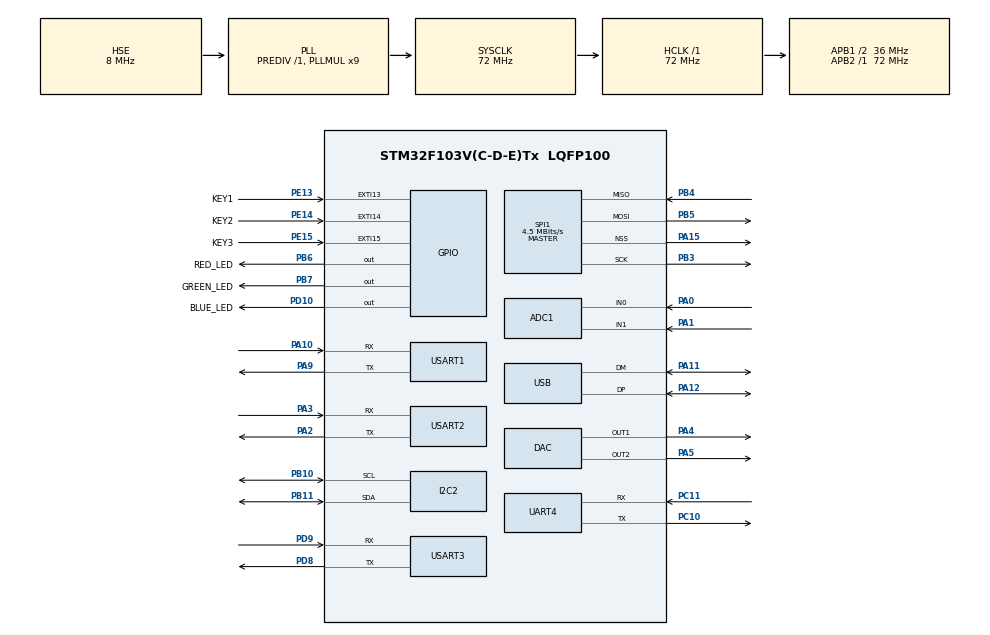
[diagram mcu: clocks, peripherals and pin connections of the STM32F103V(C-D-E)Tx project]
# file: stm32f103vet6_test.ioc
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ADC1.Channel-0\#ChannelRegularConversion=ADC_CHANNEL_0
ADC1.Channel-1\#ChannelRegularConversion=ADC_CHANNEL_1
ADC1.ContinuousConvMode=ENABLE
ADC1.EnableInjectedConversion=DISABLE
ADC1.ExternalTrigConv=ADC_SOFTWARE_START
ADC1.NbrOfConversion=2
ADC1.NbrOfConversionFlag=1
ADC1.Rank-0\#ChannelRegularConversion=1
ADC1.Rank-1\#ChannelRegularConversion=2
ADC1.SamplingTime-0\#ChannelRegularConversion=ADC_SAMPLETIME_55CYCLES_5
ADC1.SamplingTime-1\#ChannelRegularConversion=ADC_SAMPLETIME_55CYCLES_5
ADC1.master=1
Dma.ADC1.0.Direction=DMA_PERIPH_TO_MEMORY
Dma.ADC1.0.Instance=DMA1_Channel1
Dma.ADC1.0.MemDataAlignment=DMA_MDATAALIGN_HALFWORD
Dma.ADC1.0.MemInc=DMA_MINC_ENABLE
Dma.ADC1.0.Mode=DMA_CIRCULAR
Dma.ADC1.0.PeriphDataAlignment=DMA_PDATAALIGN_HALFWORD
Dma.ADC1.0.PeriphInc=DMA_PINC_DISABLE
Dma.ADC1.0.Priority=DMA_PRIORITY_LOW
Dma.Request0=ADC1
Dma.Request1=USART2_RX
Dma.Request2=USART2_TX
Dma.Request3=USART3_RX
Dma.Request4=USART3_TX
Dma.Request5=USART1_RX
Dma.Request6=USART1_TX
Dma.Request7=UART4_RX
Dma.Request8=UART4_TX
Dma.UART4_RX.7.Direction=DMA_PERIPH_TO_MEMORY
Dma.UART4_RX.7.Instance=DMA2_Channel3
Dma.UART4_RX.7.MemDataAlignment=DMA_MDATAALIGN_BYTE
Dma.UART4_RX.7.MemInc=DMA_MINC_ENABLE
Dma.UART4_RX.7.Mode=DMA_NORMAL
Dma.UART4_RX.7.PeriphDataAlignment=DMA_PDATAALIGN_BYTE
Dma.UART4_RX.7.PeriphInc=DMA_PINC_DISABLE
Dma.UART4_RX.7.Priority=DMA_PRIORITY_LOW
Dma.UART4_TX.8.Direction=DMA_MEMORY_TO_PERIPH
Dma.UART4_TX.8.Instance=DMA2_Channel5
Dma.UART4_TX.8.MemDataAlignment=DMA_MDATAALIGN_BYTE
Dma.UART4_TX.8.MemInc=DMA_MINC_ENABLE
Dma.UART4_TX.8.Mode=DMA_NORMAL
Dma.UART4_TX.8.PeriphDataAlignment=DMA_PDATAALIGN_BYTE
Dma.UART4_TX.8.PeriphInc=DMA_PINC_DISABLE
Dma.UART4_TX.8.Priority=DMA_PRIORITY_LOW
Dma.USART1_RX.5.Direction=DMA_PERIPH_TO_MEMORY
Dma.USART1_RX.5.Instance=DMA1_Channel5
Dma.USART1_RX.5.MemDataAlignment=DMA_MDATAALIGN_BYTE
Dma.USART1_RX.5.MemInc=DMA_MINC_ENABLE
Dma.USART1_RX.5.Mode=DMA_NORMAL
Dma.USART1_RX.5.PeriphDataAlignment=DMA_PDATAALIGN_BYTE
Dma.USART1_RX.5.PeriphInc=DMA_PINC_DISABLE
Dma.USART1_RX.5.Priority=DMA_PRIORITY_LOW
Dma.USART1_TX.6.Direction=DMA_MEMORY_TO_PERIPH
Dma.USART1_TX.6.Instance=DMA1_Channel4
Dma.USART1_TX.6.MemDataAlignment=DMA_MDATAALIGN_BYTE
Dma.USART1_TX.6.MemInc=DMA_MINC_ENABLE
Dma.USART1_TX.6.Mode=DMA_NORMAL
Dma.USART1_TX.6.PeriphDataAlignment=DMA_PDATAALIGN_BYTE
Dma.USART1_TX.6.PeriphInc=DMA_PINC_DISABLE
Dma.USART1_TX.6.Priority=DMA_PRIORITY_LOW
Dma.USART2_RX.1.Direction=DMA_PERIPH_TO_MEMORY
Dma.USART2_RX.1.Instance=DMA1_Channel6
Dma.USART2_RX.1.MemDataAlignment=DMA_MDATAALIGN_BYTE
Dma.USART2_RX.1.MemInc=DMA_MINC_ENABLE
Dma.USART2_RX.1.Mode=DMA_NORMAL
Dma.USART2_RX.1.PeriphDataAlignment=DMA_PDATAALIGN_BYTE
Dma.USART2_RX.1.PeriphInc=DMA_PINC_DISABLE
Dma.USART2_RX.1.Priority=DMA_PRIORITY_LOW
Dma.USART2_TX.2.Direction=DMA_MEMORY_TO_PERIPH
Dma.USART2_TX.2.Instance=DMA1_Channel7
Dma.USART2_TX.2.MemDataAlignment=DMA_MDATAALIGN_BYTE
Dma.USART2_TX.2.MemInc=DMA_MINC_ENABLE
Dma.USART2_TX.2.Mode=DMA_NORMAL
Dma.USART2_TX.2.PeriphDataAlignment=DMA_PDATAALIGN_BYTE
Dma.USART2_TX.2.PeriphInc=DMA_PINC_DISABLE
Dma.USART2_TX.2.Priority=DMA_PRIORITY_LOW
Dma.USART3_RX.3.Direction=DMA_PERIPH_TO_MEMORY
Dma.USART3_RX.3.Instance=DMA1_Channel3
Dma.USART3_RX.3.MemDataAlignment=DMA_MDATAALIGN_BYTE
Dma.USART3_RX.3.MemInc=DMA_MINC_ENABLE
Dma.USART3_RX.3.Mode=DMA_NORMAL
Dma.USART3_RX.3.PeriphDataAlignment=DMA_PDATAALIGN_BYTE
Dma.USART3_RX.3.PeriphInc=DMA_PINC_DISABLE
Dma.USART3_RX.3.Priority=DMA_PRIORITY_LOW
Dma.USART3_TX.4.Direction=DMA_MEMORY_TO_PERIPH
Dma.USART3_TX.4.Instance=DMA1_Channel2
Dma.USART3_TX.4.MemDataAlignment=DMA_MDATAALIGN_BYTE
Dma.USART3_TX.4.MemInc=DMA_MINC_ENABLE
Dma.USART3_TX.4.Mode=DMA_NORMAL
Dma.USART3_TX.4.PeriphDataAlignment=DMA_PDATAALIGN_BYTE
Dma.USART3_TX.4.PeriphInc=DMA_PINC_DISABLE
Dma.USART3_TX.4.Priority=DMA_PRIORITY_LOW
Mcu.Family=STM32F1
Mcu.Name=STM32F103V(C-D-E)Tx
Mcu.Package=LQFP100
NVIC.DMA1_Channel1_IRQn=true\:0\:0\:false\:false\:true\:false\:true\:true
NVIC.DMA1_Channel2_IRQn=true\:0\:0\:false\:false\:true\:false\:true\:true
NVIC.DMA1_Channel3_IRQn=true\:0\:0\:false\:false\:true\:false\:true\:true
NVIC.DMA1_Channel4_IRQn=true\:0\:0\:false\:false\:true\:false\:true\:true
NVIC.DMA1_Channel5_IRQn=true\:0\:0\:false\:false\:true\:false\:true\:true
NVIC.DMA1_Channel6_IRQn=true\:0\:0\:false\:false\:true\:false\:true\:true
NVIC.DMA1_Channel7_IRQn=true\:0\:0\:false\:false\:true\:false\:true\:true
NVIC.DMA2_Channel3_IRQn=true\:0\:0\:false\:false\:true\:false\:true\:true
NVIC.DMA2_Channel4_5_IRQn=true\:0\:0\:false\:false\:true\:false\:true\:true
NVIC.EXTI15_10_IRQn=true\:0\:0\:false\:false\:true\:true\:true\:true
NVIC.PriorityGroup=NVIC_PRIORITYGROUP_4
NVIC.UART4_IRQn=true\:0\:0\:false\:false\:true\:true\:true\:true
NVIC.USART1_IRQn=true\:0\:0\:false\:false\:true\:true\:true\:true
NVIC.USART2_IRQn=true\:0\:0\:false\:false\:true\:true\:true\:true
NVIC.USART3_IRQn=true\:0\:0\:false\:false\:true\:true\:true\:true
NVIC.USB_LP_CAN1_RX0_IRQn=true\:0\:0\:false\:false\:true\:false\:true\:true
OSC_IN.Mode=HSE-External-Oscillator
OSC_IN.Signal=RCC_OSC_IN
OSC_OUT.Mode=HSE-External-Oscillator
OSC_OUT.Signal=RCC_OSC_OUT
PA0-WKUP.Signal=ADCx_IN0
PA1.Signal=ADCx_IN1
PA10.Mode=Asynchronous
PA10.Signal=USART1_RX
PA11.Mode=Device
PA11.Signal=USB_DM
PA12.Mode=Device
PA12.Signal=USB_DP
PA13.Mode=Serial_Wire
PA13.Signal=SYS_JTMS-SWDIO
PA14.Mode=Serial_Wire
PA14.Signal=SYS_JTCK-SWCLK
PA15.Mode=NSS_Signal_Hard_Output
PA15.Signal=SPI1_NSS
PA2.Mode=Asynchronous
PA2.Signal=USART2_TX
PA3.Mode=Asynchronous
PA3.Signal=USART2_RX
PA4.Signal=COMP_DAC1_group
PA5.Signal=COMP_DAC2_group
PA9.Mode=Asynchronous
PA9.Signal=USART1_TX
PB10.Mode=I2C
PB10.Signal=I2C2_SCL
PB11.Mode=I2C
PB11.Signal=I2C2_SDA
PB3.Mode=Full_Duplex_Master
PB3.Signal=SPI1_SCK
PB4.Mode=Full_Duplex_Master
PB4.Signal=SPI1_MISO
PB5.Mode=Full_Duplex_Master
PB5.Signal=SPI1_MOSI
PB6.GPIO_Label=RED_LED
PB6.PinState=GPIO_PIN_SET
PB6.Signal=GPIO_Output
PB7.GPIO_Label=GREEN_LED
PB7.PinState=GPIO_PIN_SET
PB7.Signal=GPIO_Output
PC10.Mode=Asynchronous
PC10.Signal=UART4_TX
PC11.Mode=Asynchronous
PC11.Signal=UART4_RX
PC14-OSC32_IN.Mode=LSE-External-Oscillator
PC14-OSC32_IN.Signal=RCC_OSC32_IN
PC15-OSC32_OUT.Mode=LSE-External-Oscillator
PC15-OSC32_OUT.Signal=RCC_OSC32_OUT
PD10.GPIO_Label=BLUE_LED
PD10.GPIO_ModeDefaultOutputPP=GPIO_MODE_OUTPUT_PP
PD10.GPIO_PuPd=GPIO_NOPULL
PD10.PinState=GPIO_PIN_SET
PD10.Signal=GPIO_Output
PD8.Mode=Asynchronous
PD8.Signal=USART3_TX
PD9.Mode=Asynchronous
PD9.Signal=USART3_RX
PE13.GPIO_Label=KEY1
PE13.GPIO_ModeDefaultEXTI=GPIO_MODE_IT_RISING
PE13.GPIO_PuPd=GPIO_PULLUP
PE13.Signal=GPXTI13
PE14.GPIO_Label=KEY2
PE14.GPIO_ModeDefaultEXTI=GPIO_MODE_IT_RISING
PE14.GPIO_PuPd=GPIO_PULLUP
PE14.Signal=GPXTI14
PE15.GPIO_Label=KEY3
PE15.GPIO_ModeDefaultEXTI=GPIO_MODE_IT_RISING
PE15.GPIO_PuPd=GPIO_PULLUP
PE15.Signal=GPXTI15
ProjectManager.HeapSize=0x200
ProjectManager.StackSize=0x400
ProjectManager.TargetToolchain=MDK-ARM V5.32
RCC.ADCPresc=RCC_ADCPCLK2_DIV6
RCC.AHBFreq_Value=72000000
RCC.APB1CLKDivider=RCC_HCLK_DIV2
RCC.APB1Freq_Value=36000000
RCC.APB1TimFreq_Value=72000000
RCC.APB2Freq_Value=72000000
RCC.APB2TimFreq_Value=72000000
RCC.HCLKFreq_Value=72000000
RCC.PLLMUL=RCC_PLL_MUL9
RCC.RTCClockSelection=RCC_RTCCLKSOURCE_LSE
RCC.SYSCLKFreq_VALUE=72000000
RCC.SYSCLKSource=RCC_SYSCLKSOURCE_PLLCLK
RCC.USBFreq_Value=48000000
RCC.USBPrescaler=RCC_USBCLKSOURCE_PLL_DIV1_5
SH.ADCx_IN0.0=ADC1_IN0,IN0
SH.ADCx_IN1.0=ADC1_IN1,IN1
SH.COMP_DAC1_group.0=DAC_OUT1,DAC_OUT1
SH.COMP_DAC2_group.0=DAC_OUT2,DAC_OUT2
SPI1.BaudRatePrescaler=SPI_BAUDRATEPRESCALER_16
SPI1.CalculateBaudRate=4.5 MBits/s
SPI1.Direction=SPI_DIRECTION_2LINES
SPI1.Mode=SPI_MODE_MASTER
SPI1.VirtualNSS=VM_NSSHARD
SPI1.VirtualType=VM_MASTER
UART4.VirtualMode=Asynchronous
USART1.VirtualMode=VM_ASYNC
USART2.VirtualMode=VM_ASYNC
USART3.VirtualMode=VM_ASYNC
USB_DEVICE.CLASS_NAME_FS=CDC
USB_DEVICE.VirtualMode=Cdc
USB_DEVICE.VirtualModeFS=Cdc_FS
VP_RTC_VS_RTC_Activate.Mode=RTC_Enabled
VP_RTC_VS_RTC_Calendar.Mode=RTC_Calendar
VP_USB_DEVICE_VS_USB_DEVICE_CDC_FS.Mode=CDC_FS
board=custom

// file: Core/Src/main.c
/* USER CODE BEGIN Header */
/**
  ******************************************************************************
  * @file           : main.c
  * @brief          : Main program body
  ******************************************************************************
  * @attention
  *
  * Copyright (c) 2026 STMicroelectronics.
  * All rights reserved.
  *
  * This software is licensed under terms that can be found in the LICENSE file
  * in the root directory of this software component.
  * If no LICENSE file comes with this software, it is provided AS-IS.
  *
  ******************************************************************************
  */
/* USER CODE END Header */
#include "main.h"
#include "adc.h"
#include "dac.h"
#include "dma.h"
#include "i2c.h"
#include "rtc.h"
#include "spi.h"
#include "usart.h"
#include "usb_device.h"
#include "gpio.h"

/* USER CODE BEGIN Includes */
#include "uart_test.h"
#include "adc_test.h"
#include "rtc_test.h"
#include "dac_test.h"
/* USER CODE END Includes */

void SystemClock_Config(void);

int main(void)
{

  /* MCU Configuration--------------------------------------------------------*/

  /* Reset of all peripherals, Initializes the Flash interface and the Systick. */
  HAL_Init();

  /* Configure the system clock */
  SystemClock_Config();

  /* Initialize all configured peripherals */
  MX_GPIO_Init();
  MX_DMA_Init();
  MX_ADC1_Init();
  MX_DAC_Init();
  MX_I2C2_Init();
  MX_SPI1_Init();
  MX_UART4_Init();
  MX_USART1_UART_Init();
  MX_USART2_UART_Init();
  MX_USART3_UART_Init();
  MX_USB_DEVICE_Init();
  MX_RTC_Init();
  /* USER CODE BEGIN 2 */
	UartTest_Init();
	AdcTest_Init();
	RtcTest_Init();
	Dac_Init();
  /* USER CODE END 2 */

  /* Infinite loop */
  /* USER CODE BEGIN WHILE */
  while (1)
  {
    AdcTest_Print(1);
    RtcTest_Print(1);
    HAL_Delay(1000);
    /* USER CODE END WHILE */

  }
}

void SystemClock_Config(void)
{
  RCC_OscInitTypeDef RCC_OscInitStruct = {0};
  RCC_ClkInitTypeDef RCC_ClkInitStruct = {0};
  RCC_PeriphCLKInitTypeDef PeriphClkInit = {0};

  /** Initializes the RCC Oscillators according to the specified parameters
  * in the RCC_OscInitTypeDef structure.
  */
  RCC_OscInitStruct.OscillatorType = RCC_OSCILLATORTYPE_HSE|RCC_OSCILLATORTYPE_LSE;
  RCC_OscInitStruct.HSEState = RCC_HSE_ON;
  RCC_OscInitStruct.HSEPredivValue = RCC_HSE_PREDIV_DIV1;
  RCC_OscInitStruct.LSEState = RCC_LSE_ON;
  RCC_OscInitStruct.HSIState = RCC_HSI_ON;
  RCC_OscInitStruct.PLL.PLLState = RCC_PLL_ON;
  RCC_OscInitStruct.PLL.PLLSource = RCC_PLLSOURCE_HSE;
  RCC_OscInitStruct.PLL.PLLMUL = RCC_PLL_MUL9;
  if (HAL_RCC_OscConfig(&RCC_OscInitStruct) != HAL_OK)
  {
    Error_Handler();
  }

  /** Initializes the CPU, AHB and APB buses clocks
  */
  RCC_ClkInitStruct.ClockType = RCC_CLOCKTYPE_HCLK|RCC_CLOCKTYPE_SYSCLK
                              |RCC_CLOCKTYPE_PCLK1|RCC_CLOCKTYPE_PCLK2;
  RCC_ClkInitStruct.SYSCLKSource = RCC_SYSCLKSOURCE_PLLCLK;
  RCC_ClkInitStruct.AHBCLKDivider = RCC_SYSCLK_DIV1;
  RCC_ClkInitStruct.APB1CLKDivider = RCC_HCLK_DIV2;
  RCC_ClkInitStruct.APB2CLKDivider = RCC_HCLK_DIV1;

  if (HAL_RCC_ClockConfig(&RCC_ClkInitStruct, FLASH_LATENCY_2) != HAL_OK)
  {
    Error_Handler();
  }
  PeriphClkInit.PeriphClockSelection = RCC_PERIPHCLK_RTC|RCC_PERIPHCLK_ADC
                              |RCC_PERIPHCLK_USB;
  PeriphClkInit.RTCClockSelection = RCC_RTCCLKSOURCE_LSE;
  PeriphClkInit.AdcClockSelection = RCC_ADCPCLK2_DIV6;
  PeriphClkInit.UsbClockSelection = RCC_USBCLKSOURCE_PLL_DIV1_5;
  if (HAL_RCCEx_PeriphCLKConfig(&PeriphClkInit) != HAL_OK)
  {
    Error_Handler();
  }
}

void Error_Handler(void)
{
  __disable_irq();
  while (1)
  {
  }
}
